# STM32H7B3x register map
File version: 2.2
CPU: CM7 r0p1, little endian, MPU, FPU, 4 interrupt priority bits
Registers are 32-bit, read-write, reset 0x0 unless marked. A register's access mark holds for its fields unless they carry their own. Offsets are from the block's base; [hi:lo] are bit positions; lines under a group give offsets from that group; {n}, {i} and the like mark numbered series; 'fields as' and 'values as' point back to an identical list; <NAME> marks a mode.

## ADC1 — Analog to Digital Converter
Base 0x40022000
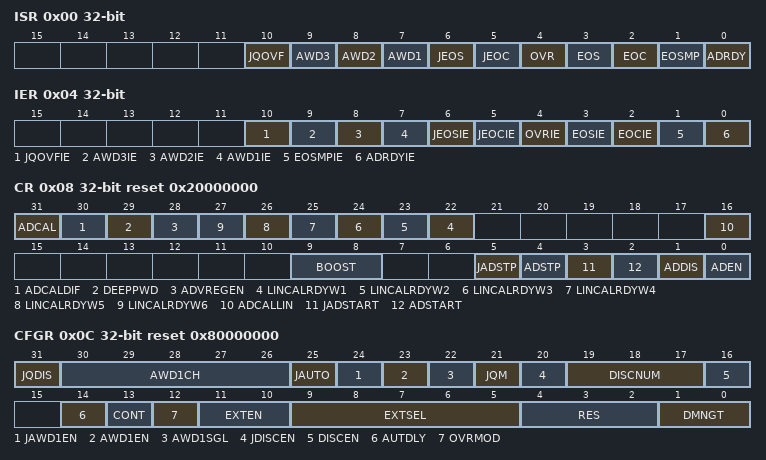
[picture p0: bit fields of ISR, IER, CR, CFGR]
0x00 ISR — ADC interrupt and status register
  [10] JQOVF — ADC group injected contexts queue overflow flag
    on read: 0=NoOverflow (No injected context queue overflow has occurred); 1=Overflow (Injected context queue overflow has occurred) | on write: 1=Clear injected context queue overflow flag
  [9] AWD3 — ADC analog watchdog 3 flag
    on read: 0=NoEvent (No analog watchdog event occurred); 1=Event (Analog watchdog event occurred) | on write: 1=Clear analog watchdog event occurred flag
  [8] AWD2 — ADC analog watchdog 2 flag
    values as AWD3
  [7] AWD1 — ADC analog watchdog 1 flag
    values as AWD3
  [6] JEOS — ADC group injected end of sequence conversions flag
    on read: 0=NotComplete (Injected sequence is not complete); 1=Complete (Injected sequence complete) | on write: 1=Clear Injected sequence complete flag
  [5] JEOC — ADC group injected end of unitary conversion flag
    on read: 0=NotComplete (Injected conversion is not complete); 1=Complete (Injected conversion complete) | on write: 1=Clear injected conversion complete flag
  [4] OVR — ADC group regular overrun flag
    on read: 0=No overrun occurred; 1=Overrun occurred | on write: 1=Clear overrun occurred flag
  [3] EOS — ADC group regular end of sequence conversions flag
    on read: 0=NotComplete (Regular sequence is not complete); 1=Complete (Regular sequence complete) | on write: 1=Clear regular sequence complete flag
  [2] EOC — ADC group regular end of unitary conversion flag
    on read: 0=NotComplete (Regular conversion is not complete); 1=Complete (Regular conversion complete) | on write: 1=Clear regular conversion complete flag
  [1] EOSMP — ADC group regular end of sampling flag
    on read: 0=NotEnded (End of sampling phase no yet reached); 1=Ended (End of sampling phase reached) | on write: 1=Clear end of sampling phase reached flag
  [0] ADRDY — ADC ready flag
    on read: 0=NotReady (ADC is not ready to start conversion); 1=Ready (ADC is ready to start conversion) | on write: 1=Clear ADC is ready to start conversion flag
0x04 IER — ADC interrupt enable register
  [10] JQOVFIE — ADC group injected contexts queue overflow interrupt
    0=Disabled (Injected context queue overflow interrupt disabled); 1=Enabled (Injected context queue overflow interrupt enabled)
  [9] AWD3IE — ADC analog watchdog 3 interrupt
    0=Disabled (Analog watchdog interrupt disabled); 1=Enabled (Analog watchdog interrupt enabled)
  [8] AWD2IE — ADC analog watchdog 2 interrupt
    values as AWD3IE
  [7] AWD1IE — ADC analog watchdog 1 interrupt
    values as AWD3IE
  [6] JEOSIE — ADC group injected end of sequence conversions interrupt
    0=Disabled (End of injected sequence interrupt disabled); 1=Enabled (End of injected sequence interrupt enabled)
  [5] JEOCIE — ADC group injected end of unitary conversion interrupt
    0=Disabled (End of injected conversion interrupt disabled); 1=Enabled (End of injected conversion interrupt enabled)
  [4] OVRIE — ADC group regular overrun interrupt
    0=Disabled (Overrun interrupt disabled); 1=Enabled (Overrun interrupt enabled)
  [3] EOSIE — ADC group regular end of sequence conversions interrupt
    0=Disabled (End of regular sequence interrupt disabled); 1=Enabled (End of regular sequence interrupt enabled)
  [2] EOCIE — ADC group regular end of unitary conversion interrupt
    0=Disabled (End of regular conversion interrupt disabled); 1=Enabled (End of regular conversion interrupt enabled)
  [1] EOSMPIE — ADC group regular end of sampling interrupt
    0=Disabled (End of regular conversion sampling phase interrupt disabled); 1=Enabled (End of regular conversion sampling phase interrupt enabled)
  [0] ADRDYIE — ADC ready interrupt
    0=Disabled (ADC ready interrupt disabled); 1=Enabled (ADC ready interrupt enabled)
0x08 CR reset 0x20000000 — ADC control register
  [31] ADCAL — ADC calibration
    0=Complete (Calibration complete); 1=Calibration (Start the calibration of the ADC)
  [30] ADCALDIF — ADC differential mode for calibration
    0=SingleEnded (Calibration for single-ended mode); 1=Differential (Calibration for differential mode)
  [29] DEEPPWD — ADC deep power down enable
    0=PowerUp (ADC not in deep power down); 1=PowerDown (ADC in deep power down)
  [28] ADVREGEN — ADC voltage regulator enable
    0=Disabled (ADC voltage regulator disabled); 1=Enabled (ADC voltage regulator enabled)
  [n+21] LINCALRDYW{n} (n=1..6) — Linearity calibration ready Word {n}
    0=Reset (LINCALFACT Word Read); 1=Set (LINCALFACT Word Write)
  [16] ADCALLIN — Linearity calibration
    0=NoLinearity (ADC calibration without linearaity calibration); 1=Linearity (ADC calibration with linearaity calibration)
  [9:8] BOOST — Boost mode control
    0=LT6_25 (Boost mode used when ADC clock ≤ 6.25 MHz); 1=LT12_5 (Boost mode used when 6.25 MHz < ADC clock ≤ 12.5 MHz); 2=LT25 (Boost mode used when 12.5 MHz < ADC clock ≤ 25.0 MHz); 3=LT50 (Boost mode used when 25.0 MHz < ADC clock ≤ 50.0 MHz)
  [5] JADSTP — ADC group injected conversion stop
    on read: 0=NotStopping (No stop command active); 1=Stopping (ADC stopping conversion) | on write: 1=StopConversion (Stop the active conversion)
  [4] ADSTP — ADC group regular conversion stop
    values as JADSTP
  [3] JADSTART — ADC group injected conversion start
    on read: 0=NotActive (No conversion ongoing); 1=Active (ADC operating and may be converting) | on write: 1=StartConversion (Start the ADC conversion (may be delayed for hardware triggers))
  [2] ADSTART — ADC group regular conversion start
    values as JADSTART
  [1] ADDIS — ADC disable
    on read: 0=NotDisabling (No disable command active); 1=Disabling (ADC disabling) | on write: 1=Disable the ADC
  [0] ADEN — ADC enable
    on read: 0=Disabled (ADC disabled); 1=Enabled (ADC enabled) | on write: 1=Enabled (Enable the ADC)
0x0C CFGR reset 0x80000000 — ADC configuration register 1
  [31] JQDIS — ADC group injected contexts queue disable
    0=Enabled (Injected Queue enabled); 1=Disabled (Injected Queue disabled)
  [30:26] AWD1CH range 0..19 — ADC analog watchdog 1 monitored channel selection
  [25] JAUTO — ADC group injected automatic trigger mode
    0=Disabled (Automatic injected group conversion disabled); 1=Enabled (Automatic injected group conversion enabled)
  [24] JAWD1EN — ADC analog watchdog 1 enable on scope ADC group injected
    0=Disabled (Analog watchdog 1 disabled on injected channels); 1=Enabled (Analog watchdog 1 enabled on injected channels)
  [23] AWD1EN — ADC analog watchdog 1 enable on scope ADC group regular
    0=Disabled (Analog watchdog 1 disabled on regular channels); 1=Enabled (Analog watchdog 1 enabled on regular channels)
  [22] AWD1SGL — ADC analog watchdog 1 monitoring a single channel or all channels
    0=All (Analog watchdog 1 enabled on all channels); 1=Single (Analog watchdog 1 enabled on single channel selected in AWD1CH)
  [21] JQM — ADC group injected contexts queue mode
    0=Mode0 (JSQR Mode 0: Queue maintains the last written configuration into JSQR); 1=Mode1 (JSQR Mode 1: An empty queue disables software and hardware triggers of the injected sequence)
  [20] JDISCEN — ADC group injected sequencer discontinuous mode
    0=Disabled (Discontinuous mode on injected channels disabled); 1=Enabled (Discontinuous mode on injected channels enabled)
  [19:17] DISCNUM — ADC group regular sequencer discontinuous number of ranks
  [16] DISCEN — ADC group regular sequencer discontinuous mode
    0=Disabled (Discontinuous mode on regular channels disabled); 1=Enabled (Discontinuous mode on regular channels enabled)
  [14] AUTDLY — ADC low power auto wait
    0=Off (Auto delayed conversion mode off); 1=On (Auto delayed conversion mode on)
  [13] CONT — ADC group regular continuous conversion mode
    0=Single conversion mode; 1=Continuous conversion mode
  [12] OVRMOD — ADC group regular overrun configuration
    0=Preserve DR register when an overrun is detected; 1=Overwrite DR register when an overrun is detected
  [11:10] EXTEN — ADC group regular external trigger polarity
    0=Disabled (Trigger detection disabled); 1=RisingEdge (Trigger detection on the rising edge); 2=FallingEdge (Trigger detection on the falling edge); 3=BothEdges (Trigger detection on both the rising and falling edges)
  [9:5] EXTSEL — ADC group regular external trigger source
    0=TIM1_CC1 (Timer 1 CC1 event); 1=TIM1_CC2 (Timer 1 CC2 event); 2=TIM1_CC3 (Timer 1 CC3 event); 3=TIM2_CC2 (Timer 2 CC2 event); 4=TIM3_TRGO (Timer 3 TRGO event); 5=TIM4_CC4 (Timer 4 CC4 event); 6=EXTI11 (EXTI line 11); 7=TIM8_TRGO (Timer 8 TRGO event); 8=TIM8_TRGO2 (Timer 8 TRGO2 event); 9=TIM1_TRGO (Timer 1 TRGO event); 10=TIM1_TRGO2 (Timer 1 TRGO2 event); 11=TIM2_TRGO (Timer 2 TRGO event); 12=TIM4_TRGO (Timer 4 TRGO event); 13=TIM6_TRGO (Timer 6 TRGO event); 14=TIM15_TRGO (Timer 15 TRGO event); 15=TIM3_CC4 (Timer 3 CC4 event); 16=HRTIM1_ADCTRG1 (HRTIM1_ADCTRG1 event); 17=HRTIM1_ADCTRG3 (HRTIM1_ADCTRG3 event); 18=LPTIM1_OUT (LPTIM1_OUT event); 19=LPTIM2_OUT (LPTIM2_OUT event); 20=LPTIM3_OUT (LPTIM3_OUT event)
  [4:2] RES — ADC data resolution
    0=SixteenBit (16-bit resolution); 1=FourteenBit (14-bit resolution in legacy mode (not optimized power consumption)); 2=TwelveBit (12-bit resolution in legacy mode (not optimized power consumption)); 3=TenBit (10-bit resolution); 5=FourteenBitV (14-bit resolution); 6=TwelveBitV (12-bit resolution); 7=EightBit (8-bit resolution)
  [1:0] DMNGT — ADC DMA transfer enable
    0=DR (Store output data in DR only); 1=DMA One Shot Mode selected; 2=DFSDM (DFSDM mode selected); 3=DMA Circular Mode selected
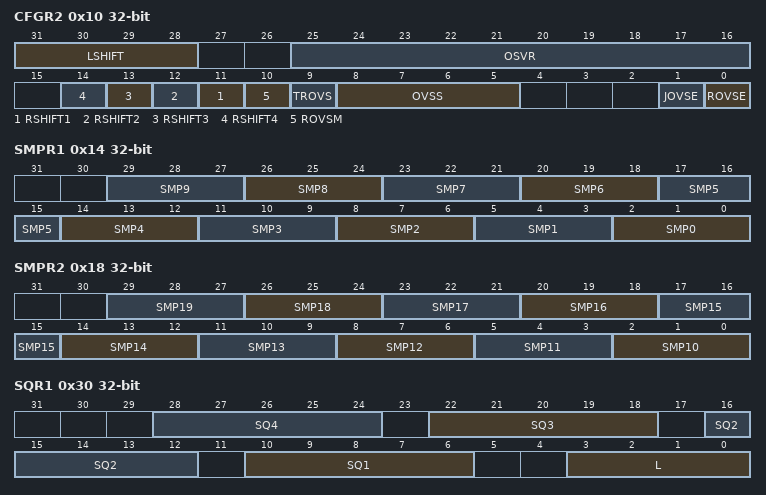
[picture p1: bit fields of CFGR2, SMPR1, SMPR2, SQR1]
0x10 CFGR2 — ADC configuration register 2
  [31:28] LSHIFT — Left shift factor
  [25:16] OSVR — Oversampling ratio
  [n+10] RSHIFT{n} (n=1..4) — Right-shift data after Offset {n} correction
    0=Disabled (Right-shifting disabled); 1=Enabled (Data is right-shifted 1-bit)
  [10] ROVSM — Regular Oversampling mode
    0=Continued (Oversampling is temporary stopped and continued after injection sequence); 1=Resumed (Oversampling is aborted and resumed from start after injection sequence)
  [9] TROVS — ADC oversampling discontinuous mode (triggered mode) for ADC group regular
    0=Automatic (All oversampled conversions for a channel are run following a trigger); 1=Triggered (Each oversampled conversion for a channel needs a new trigger)
  [8:5] OVSS range 0..11 — ADC oversampling shift
  [1] JOVSE — ADC oversampler enable on scope ADC group injected
    0=Disabled (Injected oversampling disabled); 1=Enabled (Injected oversampling enabled)
  [0] ROVSE — ADC oversampler enable on scope ADC group regular
    0=Disabled (Regular oversampling disabled); 1=Enabled (Regular oversampling enabled)
0x14 SMPR1 — ADC sampling time register 1
  [all] fields
    0=Cycles1_5 (1.5 ADC clock cycles); 1=Cycles2_5 (2.5 ADC clock cycles); 2=Cycles8_5 (8.5 ADC clock cycles); 3=Cycles16_5 (16.5 ADC clock cycles); 4=Cycles32_5 (32.5 ADC clock cycles); 5=Cycles64_5 (64.5 ADC clock cycles); 6=Cycles387_5 (387.5 ADC clock cycles); 7=Cycles810_5 (810.5 ADC clock cycles)
  [3n+2:3n] SMP{n} (n=0..9) — ADC channel {n} sampling time selection
0x18 SMPR2 — ADC sampling time register 2
  [all] fields
    values as the fields of SMPR1
  [3n-28:3n-30] SMP{n} (n=10..19) — ADC channel {n} sampling time selection
0x1C PCSEL — ADC pre channel selection register
  [19:0] PCSEL — Channel x (VINP[i]) pre selection
    0=NotPreselected (Input channel x is not pre-selected); 1=Preselected (Pre-select input channel x)
0x20 LTR1 — ADC analog watchdog 1 threshold register
  [25:0] LTR1 — ADC analog watchdog 1 threshold low
0x24 HTR1 reset 0x3FFFFFF — ADC analog watchdog 2 threshold register
  [25:0] HTR1 — ADC analog watchdog 2 threshold low
0x30 SQR1 — ADC group regular sequencer ranks register 1
  [6n+4:6n] SQ{n} range 0..19 (n=1..4) — ADC group regular sequencer rank {n}
  [3:0] L — L3
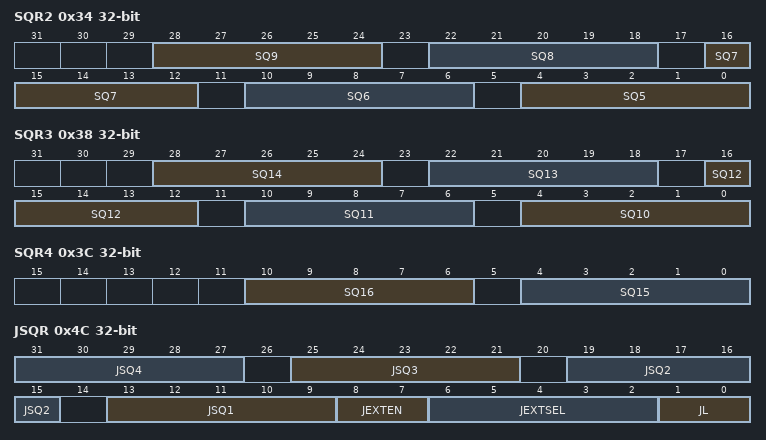
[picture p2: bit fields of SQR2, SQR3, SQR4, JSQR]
0x34 SQR2 — ADC group regular sequencer ranks register 2
  [6n-26:6n-30] SQ{n} range 0..19 (n=5..9) — ADC group regular sequencer rank {n}
0x38 SQR3 — ADC group regular sequencer ranks register 3
  [6n-56:6n-60] SQ{n} range 0..19 (n=10..14) — ADC group regular sequencer rank {n}
0x3C SQR4 — ADC group regular sequencer ranks register 4
  [10:6] SQ16 range 0..19 — ADC group regular sequencer rank 16
  [4:0] SQ15 range 0..19 — ADC group regular sequencer rank 15
0x40 DR ro — ADC group regular conversion data register
  [31:0] RDATA — ADC group regular conversion data
0x4C JSQR — ADC group injected sequencer register
  [6n+7:6n+3] JSQ{n} range 0..19 (n=1..4) — ADC group injected sequencer rank {n}
  [8:7] JEXTEN — ADC group injected external trigger polarity
    values as CFGR.EXTEN
  [6:2] JEXTSEL — ADC group injected external trigger source
    0=TIM1_TRGO (Timer 1 TRGO event); 1=TIM1_CC4 (Timer 1 CC4 event); 2=TIM2_TRGO (Timer 2 TRGO event); 3=TIM2_CC1 (Timer 2 CC1 event); 4=TIM3_CC4 (Timer 3 CC4 event); 5=TIM4_TRGO (Timer 4 TRGO event); 6=EXTI15 (EXTI line 15); 7=TIM8_CC4 (Timer 8 CC4 event); 8=TIM1_TRGO2 (Timer 1 TRGO2 event); 9=TIM8_TRGO (Timer 8 TRGO event); 10=TIM8_TRGO2 (Timer 8 TRGO2 event); 11=TIM3_CC3 (Timer 3 CC3 event); 12=TIM3_TRGO (Timer 3 TRGO event); 13=TIM3_CC1 (Timer 3 CC1 event); 14=TIM6_TRGO (Timer 6 TRGO event); 15=TIM15_TRGO (Timer 15 TRGO event); 16=HRTIM1_ADCTRG2 (HRTIM1_ADCTRG2 event); 17=HRTIM1_ADCTRG4 (HRTIM1_ADCTRG4 event); 18=LPTIM1_OUT (LPTIM1_OUT event); 19=LPTIM2_OUT (LPTIM2_OUT event); 20=LPTIM3_OUT (LPTIM3_OUT event)
  [1:0] JL — ADC group injected sequencer scan length
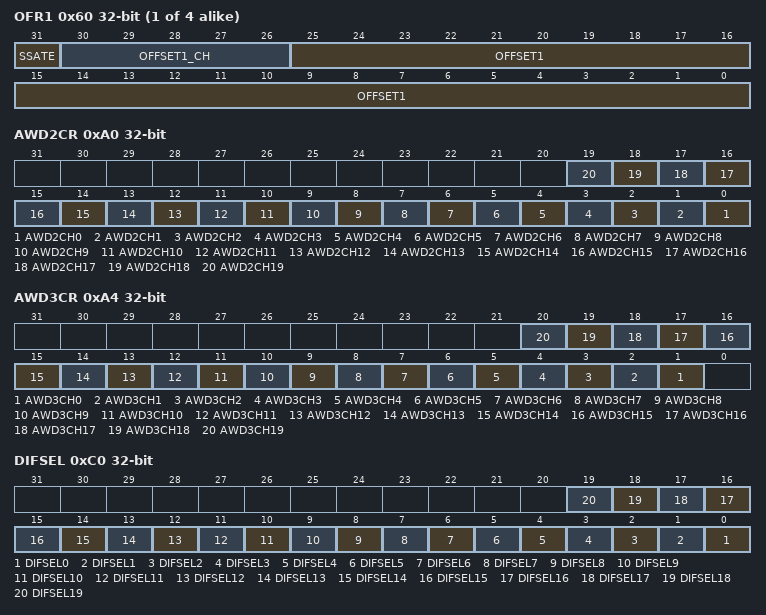
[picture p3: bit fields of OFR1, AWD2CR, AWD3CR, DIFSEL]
{0x5C+4i} OFR{i} (i=1..4) — ADC offset number {i} register
  [31] SSATE — Signed saturation enable
    0=Disabled (Offset is subtracted maintaining data integrity and extending result size (9-bit and 17-bit signed format)); 1=Enabled (Offset is subtracted and result is saturated to maintain result size)
  [30:26] OFFSET{i}_CH — ADC offset number 1 channel selection
  [25:0] OFFSET{i} — ADC offset number 1 offset level
{0x7C+4i} JDR{i} ro (i=1..4) — ADC group injected sequencer rank {i} register
  [31:0] JDATA{i} — ADC group injected sequencer rank {i} conversion data
0xA0 AWD2CR — ADC analog watchdog 2 configuration register
  [all] fields
    0=NotMonitored (Input channel not monitored by AWDx); 1=Monitored (Input channel monitored by AWDx)
  [n] AWD2CH{n} (n=0..19) — ADC analog watchdog 2 monitored channel selection
0xA4 AWD3CR — ADC analog watchdog 3 configuration register
  [all] fields
    values as the fields of AWD2CR
  [n+1] AWD3CH{n} (n=0..19) — ADC analog watchdog 3 monitored channel selection
0xB0 LTR2 — ADC watchdog lower threshold register 2
  [25:0] LTR2 — Analog watchdog 2 lower threshold
0xB4 HTR2 reset 0x3FFFFFF — ADC watchdog higher threshold register 2
  [25:0] HTR2 — Analog watchdog 2 higher threshold
0xB8 LTR3 — ADC watchdog lower threshold register 3
  [25:0] LTR3 — Analog watchdog 3 lower threshold
0xBC HTR3 reset 0x3FFFFFF — ADC watchdog higher threshold register 3
  [25:0] HTR3 — Analog watchdog 3 higher threshold
0xC0 DIFSEL — ADC channel differential or single-ended mode selection register
  [all] fields
    0=SingleEnded (Input channel is configured in single-ended mode); 1=Differential (Input channel is configured in differential mode)
  [n] DIFSEL{n} (n=0..19) — ADC channel differential or single-ended mode for channel
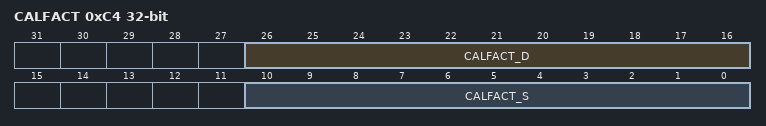
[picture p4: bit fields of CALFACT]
0xC4 CALFACT — ADC calibration factors register
  [26:16] CALFACT_D — ADC calibration factor in differential mode
  [10:0] CALFACT_S — ADC calibration factor in single-ended mode
0xC8 CALFACT2 — ADC Calibration Factor register 2
  [29:0] LINCALFACT — Linearity Calibration Factor

## ADC2 — Analog to Digital Converter
Base 0x40022100
Registers as ADC1; these are added or differ:
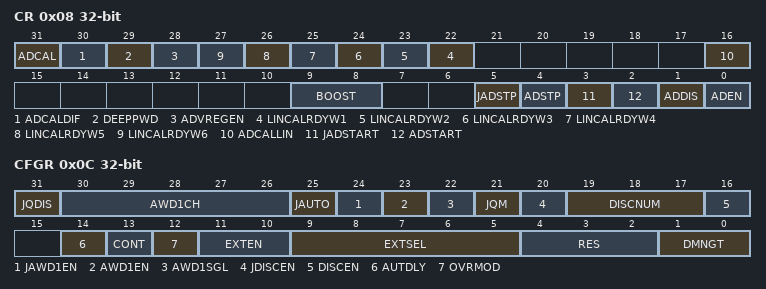
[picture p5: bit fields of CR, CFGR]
0x08 CR — ADC control register
  fields as ADC1.CR
0x0C CFGR — ADC configuration register 1
  fields as ADC1.CFGR
0x20 LTR1 reset 0xFFF0000 — ADC analog watchdog 1 threshold register
  [25:0] LTR1 — ADC analog watchdog 1 threshold low
0x24 HTR1 reset 0xFFF0000 — ADC analog watchdog 2 threshold register
  [25:0] HTR1 — ADC analog watchdog 2 threshold low
0xB4 HTR2 — ADC watchdog higher threshold register 2
  [25:0] HTR2 — Analog watchdog 2 higher threshold
0xBC HTR3 — ADC watchdog higher threshold register 3
  [25:0] HTR3 — Analog watchdog 3 higher threshold
